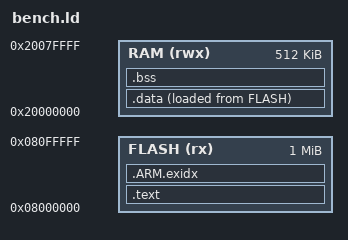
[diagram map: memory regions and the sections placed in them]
MEMORY {
  FLASH (rx) : ORIGIN = 0x08000000, LENGTH = 1M
  RAM (rwx)  : ORIGIN = 0x20000000, LENGTH = 512K
}
_estack = ORIGIN(RAM) + LENGTH(RAM);
ENTRY(Reset_Handler)
SECTIONS {
  .text : { KEEP(*(.isr_vector)) *(.text*) *(.rodata*) . = ALIGN(4); } > FLASH
  .ARM.exidx : { *(.ARM.exidx*) } > FLASH
  _sidata = LOADADDR(.data);
  .data : { _sdata = .; *(.data*) . = ALIGN(4); _edata = .; } > RAM AT > FLASH
  .bss : { _sbss = .; *(.bss*) *(COMMON) . = ALIGN(4); _ebss = .; } > RAM
}
